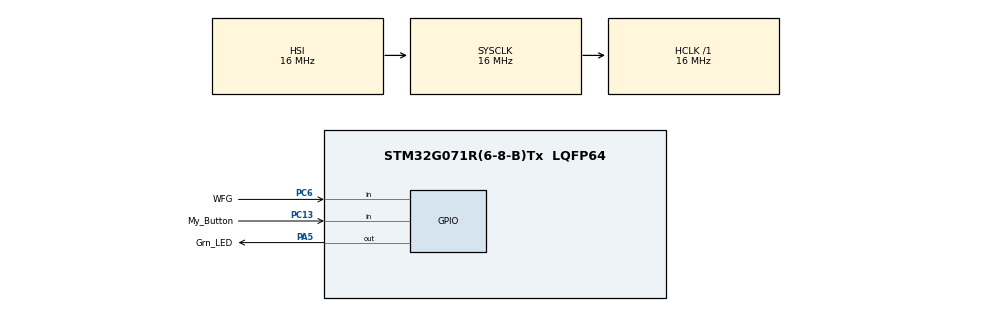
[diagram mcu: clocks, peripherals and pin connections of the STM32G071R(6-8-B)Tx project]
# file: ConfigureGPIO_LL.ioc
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Mcu.Family=STM32G0
Mcu.Name=STM32G071R(6-8-B)Tx
Mcu.Package=LQFP64
PA5.GPIO_Label=Grn_LED
PA5.Signal=GPIO_Output
PC13.GPIO_Label=My_Button
PC13.Signal=GPIO_Input
PC6.GPIO_Label=WFG
PC6.Signal=GPIO_Input
ProjectManager.HeapSize=0x200
ProjectManager.StackSize=0x400
ProjectManager.TargetToolchain=STM32CubeIDE
RCC.AHBFreq_Value=16000000
RCC.CortexFreq_Value=16000000
RCC.EXTERNAL_CLOCK_VALUE=48000
RCC.HCLKFreq_Value=16000000
RCC.HSE_VALUE=8000000
RCC.HSI_VALUE=16000000
RCC.LSE_VALUE=32768
RCC.SYSCLKFreq_VALUE=16000000
RCC.VCOOutputFreq_Value=128000000
board=custom

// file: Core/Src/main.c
/* USER CODE BEGIN Header */
/**
  ******************************************************************************
  * @file           : main.c
  * @brief          : Main program body
  ******************************************************************************
  * @attention
  *
  * Copyright (c) 2024 STMicroelectronics.
  * All rights reserved.
  *
  * This software is licensed under terms that can be found in the LICENSE file
  * in the root directory of this software component.
  * If no LICENSE file comes with this software, it is provided AS-IS.
  *
  ******************************************************************************
  */
/* USER CODE END Header */
#include "main.h"

void SystemClock_Config(void);
static void MX_GPIO_Init(void);

int main(void)
{

  /* MCU Configuration--------------------------------------------------------*/

  /* Reset of all peripherals, Initializes the Flash interface and the Systick. */
  HAL_Init();

  /* Configure the system clock */
  SystemClock_Config();

  /* Initialize all configured peripherals */
  MX_GPIO_Init();

  /* Infinite loop */
  /* USER CODE BEGIN WHILE */

  int led_state =0;
  int button_pressed=0;
  int ad2_signal_pressed = 0;
  while (1)
  {
    /* USER CODE END WHILE */
	  //button
	  if (HAL_GPIO_ReadPin(My_Button_GPIO_Port, My_Button_Pin) == GPIO_PIN_RESET)
	  {
		  if(button_pressed==0){
			  if (led_state == 0){

			  HAL_GPIO_WritePin(Grn_LED_GPIO_Port, Grn_LED_Pin, GPIO_PIN_SET);
			  led_state =1;
			  }
			  else{HAL_GPIO_WritePin(Grn_LED_GPIO_Port, Grn_LED_Pin, GPIO_PIN_RESET);
			  led_state =0;
			  }
			  button_pressed = 1;
		  }
	  }
	  else
	  {
		  button_pressed = 0;
	  }

	  //AD2 waveform generator => PC6 input

	  if (HAL_GPIO_ReadPin(WFG_GPIO_Port, WFG_Pin) == GPIO_PIN_SET) //3.3V
	  {
	      if (ad2_signal_pressed == 0) // when signal comes in first
	      {
	          if (led_state == 0)
	          {
	              HAL_GPIO_WritePin(Grn_LED_GPIO_Port, Grn_LED_Pin, GPIO_PIN_SET);
	              led_state = 1;
	          }
	          else
	          {
	              HAL_GPIO_WritePin(Grn_LED_GPIO_Port, Grn_LED_Pin, GPIO_PIN_RESET);
	              led_state = 0;
	          }
	          ad2_signal_pressed = 1; //
	      }
	  }
	  else // 0V
	  {
	      ad2_signal_pressed = 0; // To deal with the next signal

	  }

  }
}

void SystemClock_Config(void)
{
  RCC_OscInitTypeDef RCC_OscInitStruct = {0};
  RCC_ClkInitTypeDef RCC_ClkInitStruct = {0};

  /** Configure the main internal regulator output voltage
  */
  HAL_PWREx_ControlVoltageScaling(PWR_REGULATOR_VOLTAGE_SCALE1);

  /** Initializes the RCC Oscillators according to the specified parameters
  * in the RCC_OscInitTypeDef structure.
  */
  RCC_OscInitStruct.OscillatorType = RCC_OSCILLATORTYPE_HSI;
  RCC_OscInitStruct.HSIState = RCC_HSI_ON;
  RCC_OscInitStruct.HSIDiv = RCC_HSI_DIV1;
  RCC_OscInitStruct.HSICalibrationValue = RCC_HSICALIBRATION_DEFAULT;
  RCC_OscInitStruct.PLL.PLLState = RCC_PLL_NONE;
  if (HAL_RCC_OscConfig(&RCC_OscInitStruct) != HAL_OK)
  {
    Error_Handler();
  }

  /** Initializes the CPU, AHB and APB buses clocks
  */
  RCC_ClkInitStruct.ClockType = RCC_CLOCKTYPE_HCLK|RCC_CLOCKTYPE_SYSCLK
                              |RCC_CLOCKTYPE_PCLK1;
  RCC_ClkInitStruct.SYSCLKSource = RCC_SYSCLKSOURCE_HSI;
  RCC_ClkInitStruct.AHBCLKDivider = RCC_SYSCLK_DIV1;
  RCC_ClkInitStruct.APB1CLKDivider = RCC_HCLK_DIV1;

  if (HAL_RCC_ClockConfig(&RCC_ClkInitStruct, FLASH_LATENCY_0) != HAL_OK)
  {
    Error_Handler();
  }
}

static void MX_GPIO_Init(void)
{
  GPIO_InitTypeDef GPIO_InitStruct = {0};

  /* GPIO Ports Clock Enable */
  __HAL_RCC_GPIOC_CLK_ENABLE();
  __HAL_RCC_GPIOA_CLK_ENABLE();

  /*Configure GPIO pin Output Level */
  HAL_GPIO_WritePin(Grn_LED_GPIO_Port, Grn_LED_Pin, GPIO_PIN_RESET);

  /*Configure GPIO pins : My_Button_Pin WFG_Pin */
  GPIO_InitStruct.Pin = My_Button_Pin|WFG_Pin;
  GPIO_InitStruct.Mode = GPIO_MODE_INPUT;
  GPIO_InitStruct.Pull = GPIO_NOPULL;
  HAL_GPIO_Init(GPIOC, &GPIO_InitStruct);

  /*Configure GPIO pin : Grn_LED_Pin */
  GPIO_InitStruct.Pin = Grn_LED_Pin;
  GPIO_InitStruct.Mode = GPIO_MODE_OUTPUT_PP;
  GPIO_InitStruct.Pull = GPIO_NOPULL;
  GPIO_InitStruct.Speed = GPIO_SPEED_FREQ_LOW;
  HAL_GPIO_Init(Grn_LED_GPIO_Port, &GPIO_InitStruct);

}

void Error_Handler(void)
{
  __disable_irq();
  while (1)
  {
  }
}
